VERSION ""

NS_ :

BS_:

BU_: GateWay ClusterECU EngineECU TransmissionECU AccelECU BrakeECU HandleECU DriverStateWarningECU CO2SensorECU HazardLightECU windowECU

BO_ 512 frmDriverStateWarnMsg: 1 DriverStateWarningECU
 SG_ WindowOpenSig : 2|1@1+ (1,0) [0|1] ""  windowECU
 SG_ SleepinessLevel : 0|2@1+ (1,0) [0|3] ""  HazardLightECU,windowECU,HandleECU,EngineECU,ClusterECU

BO_ 513 frmCO2SensorMsg: 2 CO2SensorECU
 SG_ CO2Level : 0|12@1+ (2,0) [0|8190] ""  DriverStateWarningECU,windowECU,ClusterECU

BO_ 514 frmHazardLightMsg: 1 HazardLightECU
 SG_ LightOnStatus : 0|1@1+ (1,0) [0|1] ""  ClusterECU

BO_ 257 frmAccelMsg: 1 AccelECU
 SG_ AccelAngle : 0|5@1+ (1,0) [0|31] "Deg"  EngineECU

BO_ 256 frmBrakeMsg: 1 BrakeECU
 SG_ BrakeAngle : 0|5@1+ (1,0) [0|31] "Deg"  EngineECU

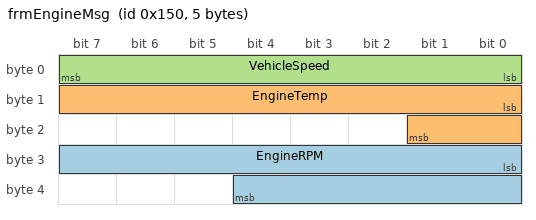
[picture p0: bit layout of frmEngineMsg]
BO_ 336 frmEngineMsg: 5 EngineECU
 SG_ EngineRPM : 24|13@1+ (1,0) [0|8191] ""  ClusterECU
 SG_ EngineTemp : 8|10@1+ (1,-20) [-20|1003] "��C"  ClusterECU
 SG_ VehicleSpeed : 0|8@1+ (1,0) [0|255] "km/s"  ClusterECU

BO_ 337 frmTransMsg: 1 TransmissionECU
 SG_ curGearStatus : 0|2@1+ (1,0) [0|3] ""  EngineECU,ClusterECU

BA_DEF_  "BusType" STRING ;
BA_DEF_DEF_  "BusType" "CAN";
